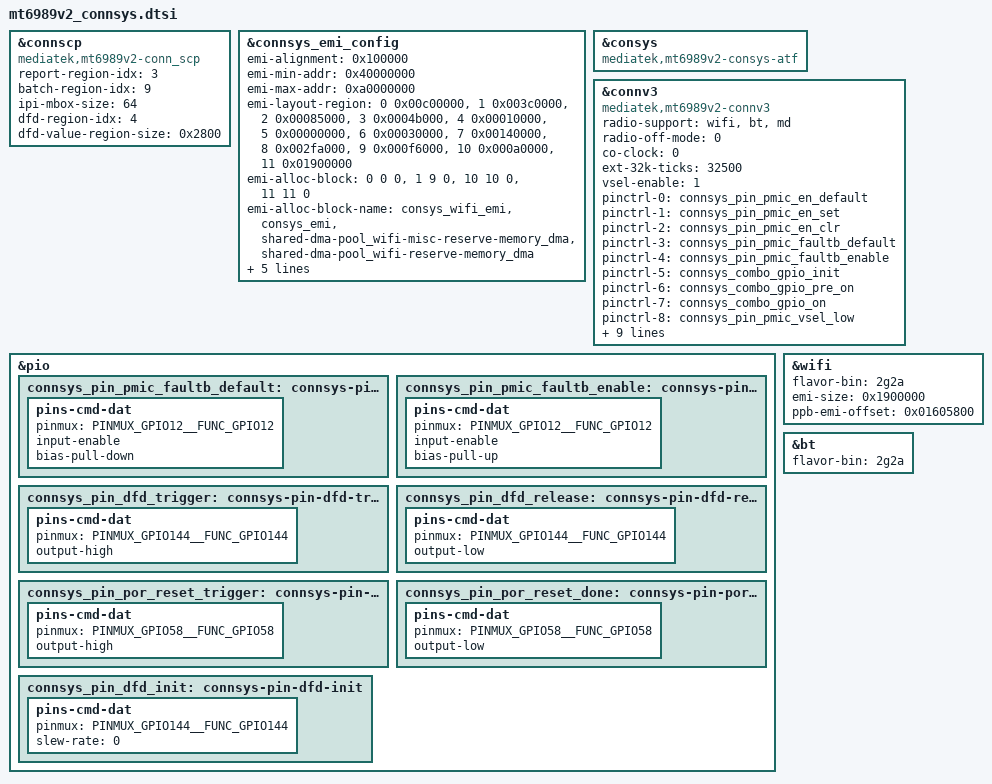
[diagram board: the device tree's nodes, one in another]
// SPDX-License-Identifier: GPL-2.0
/*
 * Copyright (c) 2024 MediaTek Inc.
 */

#include <dt-bindings/pinctrl/mt6989-pinfunc.h>
#include "mediatek/cust_mt6989v2_connfem.dtsi"

&connscp {
	compatible = "mediatek,mt6989v2-conn_scp";

	/* batching */
	report-region-idx = <3>;
	batch-region-idx = <9>;

	ipi-mbox-size = <64>;

	/* dfd */
	dfd-region-idx = <4>;
	dfd-value-region-size = <0x2800>;
};

&connsys_emi_config {
	/* emi layout settings */
	emi-alignment = <0x100000>;
	emi-min-addr = <0x40000000>;
	emi-max-addr = <0xa0000000>;

	/* EMI Layout */
	/* idx - region size */
	emi-layout-region =
		<0 0x00c00000>, /* 6653 WiFi MCU */
		<1 0x003c0000>, /* Connsys RO */
		<2 0x00085000>, /* Connsys RW */
		<3 0x0004b000>, /* SCP batching data */
		<4 0x00010000>, /* SCP DFD dump */
		<5 0x00000000>, /* Reserved for alignment */
		<6 0x00030000>, /* Connsys shared data */
		<7 0x00140000>, /* GPS_EMI */
		<8 0x002fa000>, /* MNL/MPE BIN data */
		<9 0x000f6000>, /* Connsys/SCP shared */
		<10 0x000a0000>, /* WF MISC */
		<11 0x01900000>; /* WFDMA1 */

	/* block_name start_idx end_idx mapping */
	emi-alloc-block =
		<0 0 0>,
		<1 9 0>,
		<10 10 0>,
		<11 11 0>;

	emi-alloc-block-name =
		"consys_wifi_emi",
		"consys_emi",
		"shared-dma-pool_wifi-misc-reserve-memory_dma",
		"shared-dma-pool_wifi-reserve-memory_dma";

	/* mpu region */
	/* start_idx end_idx MPU_id */
	emi-mpu-region =
		<0 0 62>,
		<1 1 44>,
		<2 5 45>,
		<6 11 47>,
		<8 9 46>;

	/* emi region to atf: start_idx end_idx */
	emi-region-to-atf = <1 7>;
	gps-emi-to-atf = <7 7>;
	emi-config-support = <1>;
};

&consys {
	compatible = "mediatek,mt6989v2-consys-atf";
};

&connv3 {
	compatible = "mediatek,mt6989v2-connv3";
	/* BT, WIFI, GPS, FM */
	radio-support = "wifi", "bt", "md";
	/* radio-off-mode: 0 means turn off pmic when all radio off */
	radio-off-mode = <0>;
	co-clock = <0>;
	ext-32k-ticks = <32500>;
	/* enable vsel or not, default is 1 (enable) for evb */
	vsel-enable = <1>;

	pinctrl-names = "connsys-pin-pmic-en-default",
			"connsys-pin-pmic-en-set",
			"connsys-pin-pmic-en-clr",
			"connsys-pin-pmic-faultb-default",
			"connsys-pin-pmic-faultb-enable",
			"connsys-combo-gpio-init",
			"connsys-combo-gpio-pre-on",
			"connsys-combo-gpio-on",
			"connsys-pin-pmic-vsel-low",
			"connsys-pin-pmic-vsel-high",
			"connsys-pin-dfd-trigger",
			"connsys-pin-dfd-release",
			"connsys-pin-por-reset-trigger",
			"connsys-pin-por-reset-done",
			"connsys-pin-dfd-init";
	pinctrl-0 = <&connsys_pin_pmic_en_default>;
	pinctrl-1 = <&connsys_pin_pmic_en_set>;
	pinctrl-2 = <&connsys_pin_pmic_en_clr>;
	pinctrl-3 = <&connsys_pin_pmic_faultb_default>;
	pinctrl-4 = <&connsys_pin_pmic_faultb_enable>;
	pinctrl-5 = <&connsys_combo_gpio_init>;
	pinctrl-6 = <&connsys_combo_gpio_pre_on>;
	pinctrl-7 = <&connsys_combo_gpio_on>;
	pinctrl-8 = <&connsys_pin_pmic_vsel_low>;
	pinctrl-9 = <&connsys_pin_pmic_vsel_high>;
	pinctrl-10 = <&connsys_pin_dfd_trigger>;
	pinctrl-11 = <&connsys_pin_dfd_release>;
	pinctrl-12 = <&connsys_pin_por_reset_trigger>;
	pinctrl-13 = <&connsys_pin_por_reset_done>;
	pinctrl-14 = <&connsys_pin_dfd_init>;

	interrupt-parent = <&pio>;
	mt6376-gpio = <&pio 12 0>,
			<&pio 152 0>;
	interrupts = <12 IRQ_TYPE_EDGE_FALLING>;
};

&pio {
	connsys_pin_pmic_faultb_default: connsys-pin-pmic-faultb-default {
		pins-cmd-dat {
			pinmux = <PINMUX_GPIO12__FUNC_GPIO12>;
			input-enable;
			bias-pull-down;
		};
	};
	connsys_pin_pmic_faultb_enable: connsys-pin-pmic-faultb-enable {
		pins-cmd-dat {
			pinmux = <PINMUX_GPIO12__FUNC_GPIO12>;
			input-enable;
			bias-pull-up;
		};
	};
	connsys_pin_dfd_trigger: connsys-pin-dfd-trigger {
		pins-cmd-dat {
			pinmux = <PINMUX_GPIO144__FUNC_GPIO144>;
			output-high;
		};
	};
	connsys_pin_dfd_release: connsys-pin-dfd-release {
		pins-cmd-dat {
			pinmux = <PINMUX_GPIO144__FUNC_GPIO144>;
			output-low;
		};
	};
	connsys_pin_por_reset_trigger: connsys-pin-por-reset-trigger {
		pins-cmd-dat {
			pinmux = <PINMUX_GPIO58__FUNC_GPIO58>;
			output-high;
		};
	};
	connsys_pin_por_reset_done: connsys-pin-por-reset-done {
		pins-cmd-dat {
			pinmux = <PINMUX_GPIO58__FUNC_GPIO58>;
			output-low;
		};
	};
	connsys_pin_dfd_init: connsys-pin-dfd-init {
		pins-cmd-dat {
			pinmux = <PINMUX_GPIO144__FUNC_GPIO144>;
			slew-rate = <0>;
		};
	};
};

&wifi {
	flavor-bin = "2g2a";
	emi-size = <0x1900000>;
	ppb-emi-offset = <0x01605800>;
};

&bt {
	flavor-bin = "2g2a";
};

/*End of this file, DO NOT ADD ANYTHING HERE*/
